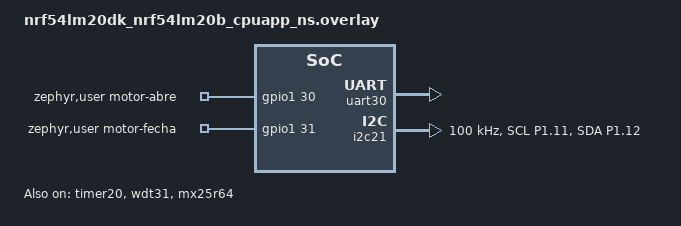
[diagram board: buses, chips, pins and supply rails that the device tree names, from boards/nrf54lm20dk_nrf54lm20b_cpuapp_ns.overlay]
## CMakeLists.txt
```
#
# Coester - SIM Connect (Gateway)
# Peripheral (interface web/celular) + Central (ate MAX_ACTUATORS
# atuadores reais via servico proprietario Coester).
#
cmake_minimum_required(VERSION 3.20.0)

find_package(Zephyr REQUIRED HINTS $ENV{ZEPHYR_BASE})
project(sim_connect_nrf54)

# NORDIC SDK APP START
target_sources(app PRIVATE
  src/main.c
  src/my_lbs.c
  src/actuator_client.c
  src/actuator_service.c
  src/uart_link.c
  src/device_health.c
  src/sensor_workq.c
  src/ads1000.c
  src/position_sensor.c
  src/torque_sensor.c
  src/torque_onoff_sensor.c
  src/sample_filter.c
  src/actuator_sensors.c
  src/actuator_params.c
  src/actuator_fsa_cfg.c
  src/actuator_torque.c
  src/watchdog.c
  src/actuator_motor.c
  src/actuator_alarm.c
  src/actuator_control.c
  src/actuator_panel.c
  src/actuator_mode.c
  src/actuator_regevent.c
)
# NORDIC SDK APP END

zephyr_library_include_directories(.)
```

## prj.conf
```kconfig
#
# Coester - SIM Connect (Gateway)
#

# Logger module
CONFIG_LOG=y

# Button and LED library
CONFIG_DK_LIBRARY=y

# --- Bluetooth LE: papel multi-role (Peripheral + varios Central) ---
CONFIG_BT=y
CONFIG_BT_PERIPHERAL=y
CONFIG_BT_CENTRAL=y
CONFIG_BT_DEVICE_NAME="Coester_Gateway"

# Nome anunciado configuravel pela propria interface web. Tentativa
# inicial (v1) usava so a Device Name padrao do GAP (servico 0x1800,
# characteristic 0x2A00) pra leitura+escrita, sem opcode customizado -
# revertido por dois motivos confirmados em campo:
#   1. Escrita nela e bloqueada por alguns navegadores/SO (Web
#      Bluetooth no Windows recusa - confirmado; escrita direta via
#      nRF Connect funciona, entao nao e o firmware).
#   2. bt_set_name() sozinho NAO persiste de forma confiavel neste
#      projeto: bt_settings_store_name() (chave embutida "bt/name" do
#      proprio Zephyr) reporta sucesso, mas o valor nao sobrevive a
#      reboot - enquanto a allow-list, no mesmo backend ZMS so que sob
#      chave nossa ("coe/al"), sobrevive normal. Bug/aspereza especifica
#      dessa integracao "bt/name" + ZMS, nao investigado a fundo.
#
# Solucao: characteristic GAP continua so LEITURA (funciona bem, e o
# navegador ja usa pra mostrar o nome atual). A ESCRITA agora e um
# opcode na nossa propria Gateway Control (GATEWAY_CTRL_SET_NAME,
# main.c) que persiste explicitamente, do nosso jeito, com o mesmo
# padrao ja confiavel da allow-list.
CONFIG_BT_DEVICE_NAME_DYNAMIC=y
CONFIG_BT_DEVICE_NAME_GATT_WRITABLE=n
CONFIG_BT_DEVICE_NAME_MAX=32

# TETO DO CONTROLADOR: o SoftDevice Controller da Nordic suporta no
# maximo 20 conexoes simultaneas somando TODOS os papeis:
#   1 interface (Peripheral) + 19 atuadores (Central) = 20
CONFIG_BT_MAX_CONN=20
CONFIG_BT_MAX_PAIRED=20

# CONFIG_BT_MAX_CONN acima e so a SOMA de todos os papeis - quantos
# podem ser Peripheral AO MESMO TEMPO e um orcamento SEPARADO
# (default 1 se nao setado). So existe 1 interface por vez, entao 1 e
# suficiente - explicito aqui, e nao no default implicito, para nao ser
# reduzido/alterado sem querer numa limpeza futura de Kconfig. Se isto
# ficar sem recurso (0 livre) enquanto a interface JA esta conectada, a
# advertising falha com HCI status 0x0d ("Limited Resources") - foi
# exatamente o que causava o loop de retentativa visto em campo quando
# um atuador reciclava a conexao com a interface ja conectada; a guarda
# em adv_work_handler() (main.c) agora evita a tentativa nesse caso, mas
# o numero fica explicito aqui pela mesma razao.
CONFIG_BT_CTLR_SDC_PERIPHERAL_COUNT=1

# Necessario para atuar como GATT Client
CONFIG_BT_GATT_CLIENT=y

# Modulo de descoberta de servicos GATT (actuator_client.c)
CONFIG_BT_GATT_DM=y

# Modulo de scan da NCS. Com os Kits B e C aposentados sobrou um unico
# filtro: o UUID do servico proprietario do atuador.
# CONFIG_BT_SCAN_UUID_CNT tem default 0 - sem reservar,
# bt_scan_filter_add() retorna -ENOMEM.
CONFIG_BT_SCAN=y
CONFIG_BT_SCAN_FILTER_ENABLE=y
CONFIG_BT_SCAN_UUID_CNT=1

# =====================================================================
# MTU - a parte mais importante desta revisao
# =====================================================================
#
# Sem estas opcoes o ATT MTU fica no default (23), ou seja 20 bytes
# uteis por notify. As respostas do protocolo proCo sao:
#
#   posicao/torque ....  18 bytes  (8 header + 10 payload)  -> cabia
#   firmware ..........  ~18 bytes                          -> cabia
#   dados gerais ......  42 bytes  (8 + 34)                 -> NAO cabia
#   curva .............  72 bytes  (8 + 64)                 -> NAO cabia
#   alarmes ........... 126 bytes  (8 + 118)                -> NAO cabia
#
# Isso explica por que a leitura de posicao/torque funcionava e as
# demais nao: era exatamente a unica que cabia em 20 bytes. O
# truncamento do bt_gatt_notify e silencioso, sem erro nenhum.
#
# Sao DOIS saltos, e os dois precisam de MTU grande:
#   atuador -> Gateway    (Gateway e Central: precisa INICIAR o MTU
#                          exchange, dai o AUTO_UPDATE_MTU abaixo)
#   Gateway -> navegador  (o navegador inicia; o Gateway so precisa de
#                          buffer)

CONFIG_BT_GATT_AUTO_UPDATE_MTU=y
CONFIG_BT_L2CAP_TX_MTU=247
CONFIG_BT_BUF_ACL_TX_SIZE=251
CONFIG_BT_BUF_ACL_RX_SIZE=251

# Data Length Extension - sem isso o MTU maior e negociado mas cada
# pacote continua fragmentado em 27 bytes de PDU, o que funciona porem
# multiplica a latencia de cada resposta grande.
CONFIG_BT_USER_DATA_LEN_UPDATE=y
CONFIG_BT_CTLR_DATA_LENGTH_MAX=251

# Mais buffers de TX: com ate 6 links centrais + a interface, o default
# vira gargalo quando varias respostas grandes chegam juntas.
#
# ATENCAO ao invariante do Zephyr:
#   CONFIG_BT_BUF_EVT_RX_COUNT > CONFIG_BT_BUF_ACL_TX_COUNT
# Cada pacote ACL enviado ao controlador gera eventos HCI de volta
# (Number of Completed Packets, principalmente). Se o host puder ter
# mais pacotes em voo do que buffers para receber os eventos que os
# liberam, ele trava esperando um buffer que so seria liberado por um
# evento sem onde chegar. Subir o ACL_TX_COUNT sem subir o EVT_RX_COUNT
# junto quebra o build com "Increase Event RX buffer count...".
# O aviso "Num of Controller's ACL packets != ACL bt_conn_tx contexts"
# no boot vem da diferenca entre estes contadores do host e o numero de
# pacotes ACL do controlador. E so um aviso de dimensionamento, nao um
# erro - mas subir o lado do controlador junto reduz o gargalo de TX
# quando varias respostas grandes chegam ao mesmo tempo.
CONFIG_BT_ATT_TX_COUNT=8
CONFIG_BT_BUF_ACL_TX_COUNT=8
CONFIG_BT_BUF_EVT_RX_COUNT=16
CONFIG_BT_CTLR_SDC_TX_PACKET_COUNT=8

# Stacks: scan + discovery + ate 19 conexoes centrais simultaneas
CONFIG_SYSTEM_WORKQUEUE_STACK_SIZE=6144
CONFIG_MAIN_STACK_SIZE=4096
CONFIG_BT_RX_STACK_SIZE=4096

# Heap: bt_gatt_dm e as multiplas conexoes centrais alocam buffers
CONFIG_HEAP_MEM_POOL_SIZE=8192

# =====================================================================
# PHY 2M
# =====================================================================
#
# Dobra a taxa no ar, reduzindo pela metade o tempo de radio de cada
# evento de conexao. Com 16 links disputando um unico radio, isso nao e
# otimizacao de luxo - e o que faz caber. O pedido e feito por link em
# actuator_client.c; se o atuador nao suportar, fica em 1M sem drama.
CONFIG_BT_CTLR_PHY_2M=y
CONFIG_BT_USER_PHY_UPDATE=y

# =====================================================================
# Persistencia da allow-list
# =====================================================================
#
# Para o nRF54L a Nordic orienta usar ZMS (Zephyr Memory Storage), nao
# NVS - o RRAM tem caracteristicas de escrita diferentes do flash. Se
# voce vier de um projeto com CONFIG_SETTINGS_NVS, esta e a migracao.
CONFIG_SETTINGS=y
CONFIG_SETTINGS_ZMS=y
CONFIG_ZMS=y
CONFIG_ZMS_LOOKUP_CACHE=y
CONFIG_ZMS_LOOKUP_CACHE_SIZE=128
CONFIG_ZMS_LOOKUP_CACHE_FOR_SETTINGS=y
CONFIG_FLASH=y
CONFIG_FLASH_MAP=y

# =====================================================================
# Agenda de radio com muitos links
# =====================================================================
#
# Limita quanto tempo um unico evento de conexao pode ocupar o radio.
# Com o default (7500 us), um link ocupado em coleta de curvas pode
# atrasar os outros 15. Reduzir aperta a coleta em lote, mas mantem o
# polling periodico regular - que e o comportamento que a demonstracao
# precisa.
#
# NOME DE KCONFIG VARIA ENTRE VERSOES DA NCS. Se o build reclamar de
# simbolo indefinido, comente esta linha: o padrao funciona, so fica
# menos justo com muitos atuadores simultaneos.
CONFIG_BT_CTLR_SDC_MAX_CONN_EVENT_LEN_DEFAULT=4000

# Descomente para ver o hexdump dos frames crus do atuador no RTT
# CONFIG_LOG_DEFAULT_LEVEL=4

# =====================================================================
# Link UART com o nRF9151 (uart_link.c)
# =====================================================================
#
# API assincrona de UART (uart_callback_set/uart_tx/uart_rx_enable) -
# mesma usada em exercises/uart-link. Ausente por padrao neste app
# porque ate a Fase 3 ele nao tinha nenhuma UART dedicada alem do
# console.
CONFIG_UART_ASYNC_API=y

# Recepcao confiavel da UARTE no nRF54L/H sem hardware flow control -
# ver nota grande no overlay de board (nrf54lm20dk_..._cpuapp_ns.overlay)
# sobre o achado em bancada (2026-08-13). Dedica TIMER20 pra contar
# bytes recebidos, evitando a perda/corrupcao de byte que a troca de
# buffer por timeout de inatividade pode causar sob latencia de
# interrupcao maior (radio BLE competindo por CPU).
CONFIG_UARTE_NRFX_UARTE_COUNT_BYTES_WITH_TIMER=y

# =====================================================================
# Sensor de posicao (potenciometro sobre ADS1000, I2C - position_sensor.c)
# =====================================================================
CONFIG_I2C=y

# Timeout por transacao I2C (default do Zephyr: 500ms) - apertado pra
# ficar mais perto da robustez do fwBLE original (TIMEOUT_TRANSACTION_
# DEFAULT=15ms em proCo/comScan.c): se uma transacao travar de verdade
# (barramento preso), o poller do sensor (ads1000.c/torque_onoff_
# sensor.c, todos na mesma fila - ver sensor_workq.c) fica bloqueado
# so' 100ms por tentativa em vez de 500ms, antes de i2c_bus_health.c
# tentar destravar o barramento - ver docs/SENSORES_I2C.md.
CONFIG_I2C_NRFX_TRANSFER_TIMEOUT=100

# Watchdog (src/watchdog.c) - task_wdt com o WDT31 como fallback de
# hardware. Motor acionado direto por GPIO: se o firmware travar com um
# pino ligado, o watchdog desliga o motor e reinicia a placa.
CONFIG_WATCHDOG=y
CONFIG_TASK_WDT=y
# Causa do ultimo reset no log de boot (saber se foi o watchdog).
CONFIG_HWINFO=y
# sys_reboot() no callback do canal estourado.
CONFIG_REBOOT=y

# Registro de eventos (src/actuator_regevent.c) na flash SPI externa
# (MX25R6435F do DK, particao event_log no overlay da placa). FLASH e
# FLASH_MAP ja estao ligados acima (settings/ZMS).
CONFIG_SPI=y
CONFIG_SPI_NOR=y
```

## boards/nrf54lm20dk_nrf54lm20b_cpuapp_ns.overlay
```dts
/*
 * Overlay para nRF54LM20-DK (target ns/TF-M - ver nota abaixo)
 * Habilita a uart30 como instancia dedicada ao link com o nRF9151.
 *
 * NAO redefine pinctrl: nrf54lm20dk_common.dtsi (arquivo nativo do
 * board, mantido pela Nordic) ja entrega current-speed, pinctrl-0/1 e
 * pinctrl-names prontos para uart30 - so falta o status="okay" abaixo.
 *
 * ACHADO EM BANCADA (2026-08-12): a primeira versao deste overlay
 * (copiada de exercises/uart-link) redefinia os pinos do zero e ERRAVA
 * - usava UART_RX em P0.08, mas o pinctrl nativo do board
 * (nrf54lm20dk_nrf54lm20_a_b-pinctrl.dtsi) diz:
 *
 *   group1: UART_TX = P0.06,  UART_RTS = P0.08
 *   group2: UART_RX = P0.07,  UART_CTS = P0.09
 *
 * P0.08 e' RTS neste board, nao RX - a redefinicao pisava em cima do
 * default correto do board com um pino errado (e descartava RTS/CTS
 * de quebra, ja que so declarava TX/RX). Sintoma visto na bancada:
 * "UART_RX_STOPPED, reason=4" (UART_ERROR_FRAMING) no lado do 91 e
 * ACK nunca recebido no lado do 54, de forma persistente.
 *
 * Fio fisico: TX do 54 = P0.06, RX do 54 = P0.07 (nao P0.08).
 *
 * NOME DO ARQUIVO IMPORTA: o nrf54-app builda para o target
 * nrf54lm20dk/nrf54lm20b/cpuapp/ns (TF-M), nao .../cpuapp (secure) como
 * exercises/uart-link. O Zephyr nomeia o overlay de board pelo target
 * INTEIRO - copiar o overlay do exercicio com o nome dele (sem "_ns")
 * faz o Zephyr simplesmente nao carregar este arquivo, sem erro de
 * build, e a uart30 fica desabilitada em silencio.
 *
 * RAIZ DA INSTABILIDADE (2026-08-13, confirmado via base de conhecimento
 * da Nordic): a UARTE do nRF54L/H (EasyDMA) so troca de buffer de
 * recepcao quando o timeout de inatividade expira, e reiniciar o
 * receptor nesse instante pode perder/corromper o byte que estava na
 * linha bem nessa hora - fica pior com latencia de interrupcao maior
 * (exatamente o efeito do radio BLE competindo por CPU/interrupcao com
 * scan+multiplas conexoes ativas). Sintoma batia exatamente com o
 * relato de outro usuario na devzone da Nordic (mesmo reason=4,
 * mesma correlacao com gaps de inatividade entre mensagens, linha
 * fisicamente limpa no osciloscopio deles). Fix documentado: dedicar
 * um TIMER pra contar bytes recebidos (CONFIG_UARTE_NRFX_UARTE_COUNT_
 * BYTES_WITH_TIMER=y no prj.conf + propriedade "timer" aqui). timer20
 * escolhido por estar livre (nada mais no projeto usa TIMER20-24).
 */

&timer20 {
	status = "okay";
};

&uart30 {
	status = "okay";
	timer = <&timer20>;
};

/*
 * I2C para o sensor de posicao (potenciometro sobre ADS1000, endereco
 * 0x49 - ver src/position_sensor.c para o porque desse endereco vs o
 * 0x92 do devices.h do proCo original).
 *
 * Sem no filho no devicetree de proposito: a leitura e crua
 * (i2c_write_read direto no registrador de conversao), no mesmo
 * espirito do exercicio validado em bancada (ncs-fund l6_e1) - evita
 * depender de um binding/driver Zephyr formal que nunca foi validado
 * (ver l7_e1, com o mesmo bug de nome de overlay descrito acima para a
 * uart30).
 *
 * i2c21 nao vem com pinctrl pronto no dtsi nativo do board (diferente
 * da uart30) - por isso, ao contrario do bloco acima, aqui precisamos
 * declarar o grupo de pinos do zero.
 */
&i2c21 {
	status = "okay";
	pinctrl-0 = <&i2c21_default>;
	pinctrl-1 = <&i2c21_sleep>;
	pinctrl-names = "default", "sleep";
	clock-frequency = <I2C_BITRATE_STANDARD>;
};

&pinctrl {
	/omit-if-no-ref/ i2c21_default: i2c21_default {
		group1 {
			psels = <NRF_PSEL(TWIM_SCL, 1, 11)>,
				    <NRF_PSEL(TWIM_SDA, 1, 12)>;
			bias-pull-up;
		};
	};
	/omit-if-no-ref/ i2c21_sleep: i2c21_sleep {
		group1 {
			psels = <NRF_PSEL(TWIM_SCL, 1, 11)>,
				    <NRF_PSEL(TWIM_SDA, 1, 12)>;
			bias-pull-up;
		};
	};
};

/*
 * Saida digital de acionamento do motor (papel atuador) - ver
 * src/actuator_motor.c. Diferente do fwBLE original (BLE/Atuador/foSeAc.c,
 * que monta uma mensagem proxiada por I2C pra uma placa FSA separada -
 * proCo/devices/devs/dev_fsa.c): o SIM Connect e' hardware unificado numa
 * placa so', sem FSA, entao o motor e' acionado direto por 2 pinos GPIO
 * do proprio nRF54 (decisao com o Felipe, 2026-09-04 - ver memoria de
 * projeto "sim-connect-command-control-port-strategy").
 *
 * P1.30 = abre, P1.31 = fecha - escolhidos em bancada, PROVISORIOS ate o
 * esquematico definitivo do circuito de acionamento existir. Trocar so'
 * os numeros de pino abaixo quando isso acontecer.
 *
 * GPIO_ACTIVE_HIGH e' um chute inicial (sem circuito de acionamento real
 * ainda pra confirmar a polaridade) - trocar pra GPIO_ACTIVE_LOW aqui se
 * o driver de motor real (rele/ponte H) for acionado em nivel baixo.
 *
 * Nao ha binding dedicado pra isto - reusa o node especial "zephyr,user"
 * (padrao do Zephyr pra GPIOs de projeto sem um binding proprio), lido em
 * actuator_motor.c via GPIO_DT_SPEC_GET(DT_PATH(zephyr_user), ..._gpios).
 */
/ {
	zephyr,user {
		motor-abre-gpios = <&gpio1 30 GPIO_ACTIVE_HIGH>;
		motor-fecha-gpios = <&gpio1 31 GPIO_ACTIVE_HIGH>;
	};
};

/* Watchdog (ver src/watchdog.c). WDT31 e' o unico WDT acessivel do lado
 * non-secure no nRF54LM20 com TF-M (WDT30 e' so' secure) - ja' e' o alias
 * watchdog0 do DK, so' vem desabilitado no dtsi.
 */
&wdt31 {
	status = "okay";
};

/* Flash SPI externa - MX25R6435F (8 MB) do DK, no spi00 (pinos nativos do
 * board: SCK P2.1, MOSI P2.2, MISO P2.4, CS P2.5, reset P2.0). Decisao
 * (2026-10-06): a placa do SIM Connect usa este mesmo chip (ou outra NOR
 * SPI compativel - o driver jedec,spi-nor le os parametros do proprio
 * chip, entao trocar e' so' devicetree). Vem desabilitada no dtsi do board.
 *
 * Uma area fixa por uso, pra um nao invadir o outro:
 *   0x000000-0x17FFFF (1,5 MB) reservado pro FOTA (slot secundario do
 *                     MCUboot, do tamanho do slot de imagem - o valor
 *                     final sai quando o MCUboot entrar; NAO usar)
 *   0x180000-0x27FFFF (1 MB)   registro de eventos (src/actuator_regevent.c,
 *                     65536 eventos de 16 bytes)
 *   0x280000-0x7FFFFF (5,5 MB) livre (curvas de torque, futuro)
 * Parametros continuam na RRAM interna (ZMS) - ver docs/REGISTRO_EVENTOS.md.
 */
&mx25r64 {
	status = "okay";

	partitions {
		compatible = "fixed-partitions";
		#address-cells = <1>;
		#size-cells = <1>;

		fota_reserved_partition: partition@0 {
			label = "fota-reserved";
			reg = <0x00000000 0x00180000>;
		};

		event_log_partition: partition@180000 {
			label = "event-log";
			reg = <0x00180000 0x00100000>;
		};
	};
};
```

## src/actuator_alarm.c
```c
/*
 * Motor de alarmes - ver actuator_alarm.h pro escopo desta primeira
 * versao (8 de ~60 alarmes do fwBLE original). O ALGORITMO abaixo
 * (tabela acao/retencao + set/release/check/get_block_mov/clears_all) e'
 * portado fielmente de BLE/Atuador/at_alarm.c - o que muda e' so' o
 * numero de linhas da tabela e as 3 dependencias externas abaixo, cada
 * uma com uma decisao de escopo explicita:
 *
 * 1. at_ctl_stop()/at_ctl_get_mov_stt() (atControle.c original) - o
 *    original tem uma dependencia CRUZADA real entre alarme e controle
 *    (atControle.c chama at_alarm_get_block_mov(), e at_alarm.c chama de
 *    volta at_ctl_stop() de dentro de al_reg_block_mov()). Como
 *    actuator_control.c ainda nao existe (passo 3), um #include direto
 *    criaria uma dependencia de link que nao compila ainda. Resolvido
 *    com o mesmo padrao de callback que actuator_client.c/my_lbs.c ja
 *    usam neste projeto pra desacoplar camadas (struct actuator_alarm_cb,
 *    ver .h) - actuator_control.c registra `stop_cb` quando existir.
 *    A segunda metade dessa dependencia (at_ctl_get_mov_stt(), usada no
 *    original só pelos modos de retenção AR_ACT_INC_INFO/AR_ACT_DEC_INFO)
 *    nao foi portada ainda porque nenhum dos 8 alarmes de hoje usa esses
 *    modos - ver o enum reduzido `actuator_alarm_retain` abaixo.
 * 2. atESDExec()/paramDado.ESDD* (al_esd_jump() original, supressao de
 *    alarme durante ESD) - ESD e' passo 6, ParamZarI e' passo 8, nenhum
 *    dos dois existe ainda. `esd_jump()` abaixo e' um stub que sempre
 *    retorna false (nenhuma supressao) - correto por enquanto porque
 *    ESD nunca esta ativo, e nenhum dos 8 alarmes de hoje e' candidato a
 *    essa supressao no original de qualquer forma (so
 *    SOBREAQUECIM/FALTA_FASE/TORQUE_AB/TORQUE_FC sao).
 * 3. atRegEvent() - portado em actuator_regevent.c. O evento leva o
 *    numero do alarme no alarm_t do fwBLE (coluna fwble_id da tabela
 *    abaixo), nao a posicao no nosso enum: EV_AL_ON/EV_AL_OFF + alarm_t
 *    e' o que um cliente do fwBLE espera. Os LOG_INF/LOG_WRN continuam
 *    pra visibilidade em RTT.
 *
 * NAO portado (avaliado e descartado, nao "esquecido"):
 * - As funcoes de display ciclico (at_alarm_get_next_view/reset_view/
 *   has_view/get_name, at_alarm_text_index[], ifIhmGetText) - existem no
 *   original pra alimentar um painel local com display. SIM Connect nao
 *   tem display fisico (ver docs/DECISOES_PRODUTO.md). Se um dia for
 *   preciso listar alarmes ativos, o caminho e' uma area/characteristic
 *   BLE nova, no mesmo espirito de PROTOCOLO_INTERFACE.md - nao esta
 *   API de ciclagem pra display.
 * - at_alarm_get_critic_fail()/at_alarm_get_pos_fail() - agregam MUITOS
 *   alarmes especificos (posicao absoluta, IO Analogica/Digital, FSA...)
 *   que nao existem no enum reduzido de hoje. Refazer quando o conjunto
 *   de 60 alarmes estiver completo.
 * - reset_check()/resetaTudo (o gatilho `dadoFSA.senFase` dentro de
 *   at_alarm_clears_all() original) - especifico de sensoriamento
 *   trifasico via FSA, que este hardware nao tem (ver
 *   docs/PORTABILIDADE_BLE_LEGADO.md e a decisao de motor por GPIO
 *   direto, memoria sim-connect-command-control-port-strategy).
 */

#include "actuator_alarm.h"
#include "actuator_regevent.h"

#include <zephyr/sys/util.h>
#include <zephyr/toolchain.h>
#include <zephyr/logging/log.h>

LOG_MODULE_REGISTER(actuator_alarm, LOG_LEVEL_INF);

/* Equivalente a al_action_t - os valores que os alarmes portados usam.
 * STOP_INCR/STOP_DECR (AA_STO_INC/AA_STO_DEC) bloqueiam so' um sentido -
 * entraram com os alarmes de torque.
 */
enum alarm_action {
	ALARM_ACTION_NONE = 0,
	ALARM_ACTION_STOP_BOTH,
	ALARM_ACTION_STOP_INCR,
	ALARM_ACTION_STOP_DECR,
};

/* Equivalente a al_retain_t - os modos que os alarmes portados usam.
 * Ainda fora (nenhum alarme portado precisa): AR_ACT_INFO, AR_CONF.
 */
enum alarm_retain {
	ALARM_RETAIN_INFO,        /* libera junto com a acao (AR_INFO) */
	ALARM_RETAIN_INFO_REMOTE, /* como INFO, mas nunca aparece num display local (AR_INFO_REMOTE) */
	ALARM_RETAIN_NOT_RETAIN,  /* libera info assim que a acao cessa, sem quitacao (AR_NOT_RETAIN) */
	ALARM_RETAIN_ACT_INC_INFO, /* release so' libera a acao com o motor FECHANDO (AR_ACT_INC_INFO) */
	ALARM_RETAIN_ACT_DEC_INFO, /* release so' libera a acao com o motor ABRINDO (AR_ACT_DEC_INFO) */
};

struct alarm_ctl_entry {
	enum alarm_action action;
	enum alarm_retain retain;
	uint8_t fwble_id; /* posicao no alarm_t do fwBLE (at_alarm.h) - id do registro de eventos */
	const char *name; /* so' pra log - nao existe no original (la' e' ifIhmGetText) */
};

/* Tabela de controle - equivalente a al_ctl[NUM_ALARMS] no original.
 * Linhas copiadas verbatim de BLE/Atuador/at_alarm.c (mesma acao/
 * retencao), na mesma ordem relativa. Adicionar um alarme = 1 linha
 * aqui (na mesma ordem do enum em actuator_alarm.h) + 1 linha no enum.
 */
static const struct alarm_ctl_entry alarm_ctl[ACTUATOR_ALARM_NUM] = {
	[ACTUATOR_ALARM_ESD_EXT] = { ALARM_ACTION_NONE, ALARM_RETAIN_INFO, 14, "ESD_EXT" },
	[ACTUATOR_ALARM_PARADA_LOCAL] = { ALARM_ACTION_NONE, ALARM_RETAIN_INFO, 15, "PARADA_LOCAL" },
	[ACTUATOR_ALARM_MODO_NAO_REMOTO] = { ALARM_ACTION_NONE, ALARM_RETAIN_INFO_REMOTE, 16,
					      "MODO_NAO_REMOTO" },
	[ACTUATOR_ALARM_LOCAL_INIBIDO] = { ALARM_ACTION_NONE, ALARM_RETAIN_NOT_RETAIN, 26,
					    "LOCAL_INIBIDO" },
	[ACTUATOR_ALARM_FAL_ACION_INV] = { ALARM_ACTION_STOP_BOTH, ALARM_RETAIN_INFO, 28,
					    "FAL_ACION_INV" },
	[ACTUATOR_ALARM_OPER_MANUAL] = { ALARM_ACTION_NONE, ALARM_RETAIN_INFO, 32, "OPER_MANUAL" },
	[ACTUATOR_ALARM_PST_EXE] = { ALARM_ACTION_NONE, ALARM_RETAIN_NOT_RETAIN, 47, "PST_EXE" },
	[ACTUATOR_ALARM_PST_FAL] = { ALARM_ACTION_NONE, ALARM_RETAIN_INFO, 48, "PST_FAL" },
	/* AL_COM_POS no fwBLE: { AA_STO_INC_DEC, AR_NOT_RETAIN } - bloqueia
	 * os dois sentidos e some sozinho quando o sensor volta a responder
	 * (sem exigir quitacao).
	 */
	[ACTUATOR_ALARM_COM_SENS_POS] = { ALARM_ACTION_STOP_BOTH, ALARM_RETAIN_NOT_RETAIN, 2,
					  "COM_SENS_POS" },
	/* Torque - linhas verbatim do at_alarm.c original:
	 *   AL_TORQUE_AB      { AA_STO_INC,     AR_ACT_INC_INFO }
	 *   AL_TORQUE_FC      { AA_STO_DEC,     AR_ACT_DEC_INFO }
	 *   AL_VALV_TRAVADA   { AA_STO_INC_DEC, AR_INFO }
	 *   AL_OPER_INCOMPLETA{ AA_NONE,        AR_INFO }
	 */
	[ACTUATOR_ALARM_TORQUE_AB] = { ALARM_ACTION_STOP_INCR, ALARM_RETAIN_ACT_INC_INFO, 11,
				       "TORQUE_AB" },
	[ACTUATOR_ALARM_TORQUE_FC] = { ALARM_ACTION_STOP_DECR, ALARM_RETAIN_ACT_DEC_INFO, 12,
				       "TORQUE_FC" },
	[ACTUATOR_ALARM_VALV_TRAVADA] = { ALARM_ACTION_STOP_BOTH, ALARM_RETAIN_INFO, 13,
					  "VALV_TRAVADA" },
	[ACTUATOR_ALARM_OPER_INCOMPLETA] = { ALARM_ACTION_NONE, ALARM_RETAIN_INFO, 17,
					     "OPER_INCOMPLETA" },
	/* AL_COM_TRQ no fwBLE: { AA_STO_INC_DEC, AR_NOT_RETAIN } - mesmo
	 * comportamento do COM_SENS_POS: bloqueia os dois sentidos e some
	 * sozinho quando o sensor volta.
	 */
	[ACTUATOR_ALARM_COM_SENS_TRQ] = { ALARM_ACTION_STOP_BOTH, ALARM_RETAIN_NOT_RETAIN, 3,
					  "COM_SENS_TRQ" },
};

/* O bitmap da area de status (actuator_alarm_info_bitmap) e' u16 */
BUILD_ASSERT(ACTUATOR_ALARM_NUM <= 16, "bitmap de alarmes da area de status tem 16 bits");

struct alarm_status {
	bool action;
	bool info;
};

static struct alarm_status alarm_stt[ACTUATOR_ALARM_NUM];
static bool block_mov;
static struct actuator_alarm_cb callbacks;

static inline bool alarm_valid(enum actuator_alarm_id alarm)
{
	return alarm < ACTUATOR_ALARM_NUM;
}

static inline const char *alarm_name(enum actuator_alarm_id alarm)
{
	return alarm_valid(alarm) ? alarm_ctl[alarm].name : "?";
}

/* Equivalente a al_esd_jump() - ver dependencia 2 no comentario do topo. */
static bool esd_jump(enum actuator_alarm_id alarm)
{
	(void)alarm;
	return false;
}

/* Equivalente a al_reg_set() - registra a transicao pra ativo. */
static void reg_set(enum actuator_alarm_id alarm)
{
	if (!alarm_stt[alarm].action) {
		alarm_stt[alarm].action = true;
		alarm_stt[alarm].info = true;
		LOG_INF("Alarme ATIVADO: %s", alarm_name(alarm));
		actuator_regevent(EV_AL_ON + alarm_ctl[alarm].fwble_id);
	}
}

/* Equivalente a al_reg_release(). */
static void reg_release(enum actuator_alarm_id alarm)
{
	if (alarm_stt[alarm].action) {
		alarm_stt[alarm].action = false;
		LOG_INF("Alarme desativado: %s", alarm_name(alarm));
		actuator_regevent(EV_AL_OFF + alarm_ctl[alarm].fwble_id);
	}
}

/* Equivalente a al_reg_block_mov() - dispara o callback de parada (se
 * registrado, ver dependencia 1 no topo) toda vez que e' chamado, igual
 * ao original (nao so' na borda).
 */
static void reg_block_mov(enum actuator_alarm_id alarm)
{
	if (!block_mov) {
		block_mov = true;
		LOG_WRN("Movimento bloqueado por alarme: %s", alarm_name(alarm));
		actuator_regevent(EV_AL_BQ);
	}
	if (callbacks.stop_cb) {
		callbacks.stop_cb();
	}
}

void actuator_alarm_init(const struct actuator_alarm_cb *cb)
{
	for (int i = 0; i < ACTUATOR_ALARM_NUM; i++) {
		alarm_stt[i].action = false;
		alarm_stt[i].info = false;
	}
	block_mov = false;

	if (cb) {
		callbacks = *cb;
	} else {
		callbacks.stop_cb = NULL;
		callbacks.mov_stt_cb = NULL;
	}

	LOG_INF("Motor de alarmes iniciado (%d de ~60 alarmes do fwBLE portados)", ACTUATOR_ALARM_NUM);
}

void actuator_alarm_set(enum actuator_alarm_id alarm)
{
	if (alarm_valid(alarm)) {
		reg_set(alarm);
	}
}

void actuator_alarm_release(enum actuator_alarm_id alarm)
{
	if (!alarm_valid(alarm)) {
		return;
	}

	switch (alarm_ctl[alarm].retain) {
	case ALARM_RETAIN_NOT_RETAIN:
		reg_release(alarm);
		alarm_stt[alarm].info = false;
		break;
	case ALARM_RETAIN_INFO:
	case ALARM_RETAIN_INFO_REMOTE:
		reg_release(alarm);
		break;
	case ALARM_RETAIN_ACT_INC_INFO:
		/* Sobretorque abrindo: o bloqueio de abrir so' sai quando o motor
		 * estiver fechando (ou pelo volante, action_clear).
		 */
		if (callbacks.mov_stt_cb && callbacks.mov_stt_cb() == ACTUATOR_MOV_DECR) {
			reg_release(alarm);
		}
		break;
	case ALARM_RETAIN_ACT_DEC_INFO:
		if (callbacks.mov_stt_cb && callbacks.mov_stt_cb() == ACTUATOR_MOV_INCR) {
			reg_release(alarm);
		}
		break;
	}

	/* Confere consistencia - se por algum motivo a acao ainda estiver
	 * ativa (ex.: retencao nao liberou), o info tem que refletir isso.
	 */
	if (alarm_stt[alarm].action) {
		alarm_stt[alarm].info = true;
	}
}

void actuator_alarm_action_clear(enum actuator_alarm_id alarm)
{
	if (alarm_valid(alarm)) {
		reg_release(alarm);
	}
}

void actuator_alarm_check(bool active, enum actuator_alarm_id alarm)
{
	if (active) {
		actuator_alarm_set(alarm);
	} else {
		actuator_alarm_release(alarm);
	}
}

bool actuator_alarm_get_action(enum actuator_alarm_id alarm)
{
	return alarm_valid(alarm) ? alarm_stt[alarm].action : false;
}

bool actuator_alarm_get_info(enum actuator_alarm_id alarm)
{
	if (!alarm_valid(alarm)) {
		return false;
	}
	/* A acao sempre e' informada, mesmo se info==false por algum motivo. */
	return alarm_stt[alarm].action || alarm_stt[alarm].info;
}

bool actuator_alarm_get_block_mov(enum actuator_mov_status at_status)
{
	for (int i = 0; i < ACTUATOR_ALARM_NUM; i++) {
		if (!alarm_stt[i].action) {
			continue;
		}

		/* Info sempre acompanha uma acao ativa. */
		alarm_stt[i].info = true;

		if (esd_jump((enum actuator_alarm_id)i)) {
			continue;
		}

		switch (alarm_ctl[i].action) {
		case ALARM_ACTION_STOP_BOTH:
			if (at_status == ACTUATOR_MOV_INCR || at_status == ACTUATOR_MOV_DECR) {
				reg_block_mov((enum actuator_alarm_id)i);
				return true;
			}
			break;
		case ALARM_ACTION_STOP_INCR:
			if (at_status == ACTUATOR_MOV_INCR) {
				reg_block_mov((enum actuator_alarm_id)i);
				return true;
			}
			break;
		case ALARM_ACTION_STOP_DECR:
			if (at_status == ACTUATOR_MOV_DECR) {
				reg_block_mov((enum actuator_alarm_id)i);
				return true;
			}
			break;
		case ALARM_ACTION_NONE:
			break;
		}
	}

	block_mov = false;
	return false;
}

void actuator_alarm_clears_all(enum actuator_alarm_clear_mode mode)
{
	bool cleaned = false;

	/* DIVERGENCIA do fwBLE: o original marca `cleaned` pra QUALQUER alarme
	 * inativo (logava EV_LOC_QT a cada chamada). Aqui so' conta quando de
	 * fato limpa uma sinalizacao (info true -> false) - importante porque
	 * o bit ack_alarm do Painel Remoto nao e' auto-limpo, entao esta
	 * funcao e' chamada a cada ciclo enquanto ele estiver setado.
	 */
	for (int i = 0; i < ACTUATOR_ALARM_NUM; i++) {
		if (!alarm_stt[i].action && alarm_stt[i].info) {
			alarm_stt[i].info = false;
			cleaned = true;
		}
	}

	if (cleaned) {
		LOG_INF("Alarmes quitados (%s)",
			mode == ACTUATOR_ALARM_CLEAR_LOCAL ? "local/BLE" : "remoto");
		actuator_regevent(mode == ACTUATOR_ALARM_CLEAR_LOCAL ? EV_LOC_QT : EV_REM_QT);
	}
}

bool actuator_alarm_get_blocked(void)
{
	return block_mov;
}

uint16_t actuator_alarm_info_bitmap(void)
{
	uint16_t bm = 0;

	for (int i = 0; i < ACTUATOR_ALARM_NUM; i++) {
		if (alarm_stt[i].action || alarm_stt[i].info) {
			bm |= BIT(i);
		}
	}
	return bm;
}
```

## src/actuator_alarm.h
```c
/*
 * Motor de alarmes do papel atuador - porta de BLE/Atuador/at_alarm.c
 * (fwBLE original, ~60 alarmes reais, ver ControleCoesterBLE) pra este
 * projeto. Ver a nota grande no .c pro raciocinio completo (o que foi
 * portado 1:1, o que foi deliberadamente reduzido/adiado, e por que).
 *
 * ESCOPO DESTA PRIMEIRA VERSAO (decidido com o Felipe, 2026-09-04): so'
 * os 8 alarmes que atControle.c/atModo.c/atESD.c/atPST.c realmente
 * consultam pra bloquear movimento ou sinalizar estado - nao os ~60 do
 * original. O MOTOR (o algoritmo: tabela acao/retencao, set/release/
 * check/get_block_mov/clears_all) e' portado por inteiro e fielmente -
 * a reducao e' so' no numero de LINHAS da tabela `alarm_ctl`, que foi
 * desenhada pra crescer por "append" (mesmo em espirito do resto do
 * projeto - ver docs/SENSORES_I2C.md, alarmes ficaram na fila la' desde
 * a portagem dos sensores).
 *
 * ATENCAO - risco de fidelidade em aberto: os valores numericos deste
 * enum (`enum actuator_alarm_id`) NAO preservam a posicao exata do
 * `alarm_t` original (que tem ~60 entradas; aqui so' declaramos as 8
 * portadas, na mesma ORDEM RELATIVA mas sem os "buracos" das que faltam).
 * Isso e' seguro enquanto nada expuser o numero do alarme cru por um
 * canal externo (BLE, RS485...) esperando bater com o valor do fwBLE -
 * ate' hoje nenhuma area do protocolo BLE documentada
 * (docs/PROTOCOLO_INTERFACE.md, docs/SENSORES_I2C.md) faz isso. Se um
 * dia isso for necessario (ex.: replicar uma area "lista de alarmes" do
 * ifFerConfig pra compatibilidade com Gateway real), os 60 valores
 * precisam ser alocados de verdade, na mesma posicao do original -
 * revisitar antes de expor isto por BLE.
 */
#ifndef ACTUATOR_ALARM_H_
#define ACTUATOR_ALARM_H_

#include <stdbool.h>
#include <stdint.h>

/* Os alarmes portados ate agora - mesma ordem relativa do enum
 * `alarm_t` original (BLE/Atuador/at_alarm.h), so sem os ~52 que faltam.
 * Adicionar um alarme novo = 1 linha aqui + 1 linha na tabela
 * `alarm_ctl` em actuator_alarm.c (ver comentario la).
 */
enum actuator_alarm_id {
	ACTUATOR_ALARM_ESD_EXT = 0,    /* Comando de ESD e visto como alarme (AL_ESD_EXT) */
	ACTUATOR_ALARM_PARADA_LOCAL,   /* AL_PARADA_LOCAL */
	ACTUATOR_ALARM_MODO_NAO_REMOTO, /* AL_MODO_NAO_REMOTO */
	ACTUATOR_ALARM_LOCAL_INIBIDO,  /* AL_LOCAL_INIBIDO */
	ACTUATOR_ALARM_FAL_ACION_INV,  /* AL_FAL_ACION_INV - acionamento invertido */
	ACTUATOR_ALARM_OPER_MANUAL,    /* AL_OPER_MANUAL - movimento pelo volante */
	ACTUATOR_ALARM_PST_EXE,        /* AL_PST_EXE - PST em execucao */
	ACTUATOR_ALARM_PST_FAL,        /* AL_PST_FAL - PST falhou */
	ACTUATOR_ALARM_COM_SENS_POS,   /* AL_COM_POS - falha de comunicacao com o sensor de posicao.
				        * Anexado no fim (fora da ordem relativa do fwBLE, onde
				        * AL_COM_POS vem antes) pra nao deslocar os bits ja
				        * existentes - ver a nota de risco de fidelidade acima. */
	/* Alarmes de torque (sptTratTrq() em sensPosTor.c) - anexados no fim
	 * pelo mesmo motivo do COM_SENS_POS (bits 9..12).
	 */
	ACTUATOR_ALARM_TORQUE_AB,       /* AL_TORQUE_AB - sobretorque abrindo; bloqueia so' abrir */
	ACTUATOR_ALARM_TORQUE_FC,       /* AL_TORQUE_FC - sobretorque fechando; bloqueia so' fechar */
	ACTUATOR_ALARM_VALV_TRAVADA,    /* AL_VALV_TRAVADA - torque nos dois sentidos; bloqueia os dois */
	ACTUATOR_ALARM_OPER_INCOMPLETA, /* AL_OPER_INCOMPLETA - comando remoto abortado por torque */
	ACTUATOR_ALARM_COM_SENS_TRQ,    /* AL_COM_TRQ - nenhuma fonte de torque online (bit 13) */
	ACTUATOR_ALARM_NUM,
};

/* Status de movimento - espelha at_ctl_mov_stt_t (atControle.h no
 * original: AS_L_SUPER/AS_L_INFER/AS_INCR/AS_DECR/AS_M_PARA). Vive aqui
 * (nao em actuator_control.c, que ainda nao existe - passo 3) porque
 * actuator_alarm_get_block_mov() precisa do tipo agora; quando
 * actuator_control.c for portado, ele deve REUSAR este mesmo enum (nao
 * duplicar) - ver nota grande no .c sobre a dependencia cruzada entre
 * controle e alarme que ja existe no original.
 */
enum actuator_mov_status {
	ACTUATOR_MOV_L_SUPER = 1,
	ACTUATOR_MOV_L_INFER,
	ACTUATOR_MOV_INCR,
	ACTUATOR_MOV_DECR,
	ACTUATOR_MOV_PARADO,
};

/* Equivalente a al_clear_mode_t - ver a decisao "BLE = Local" na memoria
 * de projeto sim-connect-command-control-port-strategy: quando
 * actuator_mode.c (passo 5) existir, uma quitacao vinda da interface BLE
 * usa ACTUATOR_ALARM_CLEAR_LOCAL, RS485/MB TCP/MQTT usam _REMOTE.
 */
enum actuator_alarm_clear_mode {
	ACTUATOR_ALARM_CLEAR_LOCAL,
	ACTUATOR_ALARM_CLEAR_REMOTE,
};

/* Hook pro passo 3 (actuator_control.c, ainda nao existe) preencher -
 * ver nota grande no .c sobre por que isto e' um callback opcional em
 * vez de um #include direto de actuator_control.h. Passar NULL em
 * actuator_alarm_init() pra "sem callback ainda" (comportamento de hoje).
 */
struct actuator_alarm_cb {
	/* Forca parada do movimento - equivalente a at_ctl_stop(ACP_ALARME)
	 * dentro de al_reg_block_mov() no original. Chamado quando
	 * actuator_alarm_get_block_mov() encontra um alarme bloqueando.
	 */
	void (*stop_cb)(void);

	/* Status de movimento atual - equivalente a at_ctl_get_mov_stt()
	 * chamado dentro de at_alarm_release() no original, so' pelos modos
	 * de retencao AR_ACT_INC_INFO/AR_ACT_DEC_INFO (alarmes de torque:
	 * o bloqueio de um sentido so' sai quando o motor vai no outro).
	 * NULL = esses alarmes nunca liberam por release (so' por
	 * actuator_alarm_action_clear()).
	 */
	enum actuator_mov_status (*mov_stt_cb)(void);
};

/* Zera o estado de todos os alarmes (equivalente a at_alarm_ini_pu()) e
 * registra os callbacks pro passo 3 (cb pode ser NULL - "sem callback
 * ainda", que e' o caso hoje).
 */
void actuator_alarm_init(const struct actuator_alarm_cb *cb);

/* Ativa o alarme indicado (equivalente a at_alarm_set()). */
void actuator_alarm_set(enum actuator_alarm_id alarm);

/* Libera o alarme indicado, respeitando o modo de retencao da tabela
 * (equivalente a at_alarm_release()).
 */
void actuator_alarm_release(enum actuator_alarm_id alarm);

/* Libera a ACAO do alarme incondicionalmente, ignorando o modo de
 * retencao (equivalente a at_alarm_action_clear()). Usado quando o
 * volante e' mexido: libera os bloqueios de torque mesmo sem inverter o
 * sentido. A sinalizacao (info) continua ate' ser quitada.
 */
void actuator_alarm_action_clear(enum actuator_alarm_id alarm);

/* Ativa ou libera conforme `active` (equivalente a at_alarm_check()). */
void actuator_alarm_check(bool active, enum actuator_alarm_id alarm);

/* true se o alarme esta ativo agora (equivalente a at_alarm_get_action()). */
bool actuator_alarm_get_action(enum actuator_alarm_id alarm);

/* true se deve ser exibido/sinalizado (ativo, ou ainda nao quitado -
 * equivalente a at_alarm_get_info()).
 */
bool actuator_alarm_get_info(enum actuator_alarm_id alarm);

/* Percorre os alarmes ativos e retorna true se algum bloqueia o
 * movimento pedido em `at_status` (so' ACTUATOR_MOV_INCR/_DECR importam
 * aqui) - equivalente a at_alarm_get_block_mov(). Chama o stop_cb
 * (se registrado) no primeiro alarme bloqueante encontrado, igual ao
 * original.
 */
bool actuator_alarm_get_block_mov(enum actuator_mov_status at_status);

/* Quita (limpa a sinalizacao de) todo alarme cuja acao ja tenha cessado -
 * equivalente a at_alarm_clears_all(). NAO afeta alarmes ainda ativos.
 */
void actuator_alarm_clears_all(enum actuator_alarm_clear_mode mode);

/* true se o motor esta bloqueado por algum alarme agora - equivalente a
 * at_alarm_get_blocked().
 */
bool actuator_alarm_get_blocked(void);

/* Bitmap dos alarmes a sinalizar (bit i = actuator_alarm_get_info(i)).
 * Nao existe no fwBLE (la' a area de alarmes e' o al_stt[] inteiro, 60
 * entradas x 2 bytes) - aqui e' um resumo compacto pra area sintetica
 * que actuator_service.c expoe pra interface. Ver a nota de risco de
 * fidelidade no topo deste header.
 */
uint16_t actuator_alarm_info_bitmap(void);

#endif /* ACTUATOR_ALARM_H_ */
```

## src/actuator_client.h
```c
/*
 * Coester - SIM Connect (Gateway)
 *
 * Actuator Manager: gerencia ate MAX_ACTUATORS conexoes Central
 * simultaneas com atuadores REAIS (produto Coester, nRF52832,
 * protocolo proCo/ifFerConfig sobre servico proprietario estilo NUS).
 *
 * Sem NENHUM parsing do protocolo proCo aqui.
 *
 * --- Escala e o teto de 20 conexoes ---
 *
 * O SoftDevice Controller da Nordic suporta no maximo 20 conexoes
 * simultaneas somando TODOS os papeis. A conta do Gateway:
 *
 *     20 total
 *      -1 interface (navegador/celular, papel Peripheral)
 *     ----
 *      19 atuadores reais
 *
 * Os Kits B e C do exercicio original da Nordic foram aposentados
 * justamente por consumirem duas dessas conexoes sem fazer parte do
 * produto. Passar de 20 exigiria trocar para o controlador do Zephyr
 * (CONFIG_BT_LL_SW_SPLIT, qualificado ate 64), mas ai o gargalo deixa
 * de ser software e vira agenda de radio.
 *
 * Com 19 + 1 interface o teto fica exatamente cheio. Se um atuador cair
 * e voltar a anunciar antes de o objeto de conexao antigo ser reciclado,
 * a tentativa de reconexao falha com -ENOMEM e o Gateway tenta de novo na
 * varredura seguinte - atraso de alguns segundos, sem consequencia.
 *
 * --- Intervalo de conexao: lento por padrao, rapido sob demanda ---
 *
 * IMPORTANTE: o enlace NAO morre por falta de trafego da aplicacao. O
 * controlador troca pacotes vazios a cada intervalo de conexao
 * automaticamente; o supervision timeout so expira quando eventos
 * consecutivos sao PERDIDOS (fora de alcance, interferencia). Fazer
 * polling a cada 5 s ou a cada 5 min e indiferente para a sobrevivencia
 * do link - quem o mantem vivo e o intervalo de conexao, nao o
 * setInterval da interface.
 *
 * O que o intervalo realmente controla e o trade-off:
 *
 *   intervalo curto (15 ms)  -> round trip ~30 ms, poucos links cabem
 *   intervalo longo (200 ms) -> round trip ~400 ms, muitos links cabem
 *
 * Polling periodico de 16 atuadores quer intervalo longo. Baixar uma
 * curva de 200 registros quer intervalo curto (a 400 ms por round trip
 * e 2 round trips por registro, seriam ~3 minutos por atuador).
 *
 * A saida e nao escolher: todo link fica LENTO por padrao, e a
 * interface pede modo RAPIDO no slot especifico antes de uma coleta em
 * lote, voltando ao lento no fim.
 */

#ifndef ACTUATOR_CLIENT_H_
#define ACTUATOR_CLIENT_H_

#ifdef __cplusplus
extern "C" {
#endif

#include <zephyr/types.h>
#include <zephyr/bluetooth/addr.h>
#include <zephyr/bluetooth/conn.h>
#include <zephyr/bluetooth/gatt.h>
#include <bluetooth/gatt_dm.h>

/* UUIDs do protocolo proprietario Coester - identicas as usadas em
 * coleta_ble/ble/protocol.py. Se o produto mudar, atualize aqui E la.
 */
#define BT_UUID_ACTUATOR_SERVICE_VAL \
	BT_UUID_128_ENCODE(0x06290001, 0x0538, 0x408d, 0x8359, 0xe83d95ae1d60)
#define BT_UUID_ACTUATOR_RX_VAL \
	BT_UUID_128_ENCODE(0x06290002, 0x0538, 0x408d, 0x8359, 0xe83d95ae1d60)
#define BT_UUID_ACTUATOR_TX_VAL \
	BT_UUID_128_ENCODE(0x06290003, 0x0538, 0x408d, 0x8359, 0xe83d95ae1d60)

#define BT_UUID_ACTUATOR_SERVICE BT_UUID_DECLARE_128(BT_UUID_ACTUATOR_SERVICE_VAL)
#define BT_UUID_ACTUATOR_RX      BT_UUID_DECLARE_128(BT_UUID_ACTUATOR_RX_VAL)
#define BT_UUID_ACTUATOR_TX      BT_UUID_DECLARE_128(BT_UUID_ACTUATOR_TX_VAL)

/* Ver a nota sobre o teto de 20 conexoes no cabecalho. Se subir isto,
 * suba CONFIG_BT_MAX_CONN junto - e nao passe de
 * 20 - (1 interface + kits de teste em uso).
 */
#define MAX_ACTUATORS 19

#define MAX_DISCOVERED 12

/* --- Formato de bytes exposto a interface web ---
 *
 * O "nome" aqui é o mesmo campo que o coleta_ble mostra como TAG do
 * atuador (scanner.py usa device.name — o Local Name do advertisement
 * BLE). O Gateway agora captura esse mesmo campo, para a interface web
 * poder identificar o atuador por nome, não só por endereço.
 *
 * Registro de STATUS (41 bytes), identico no read e no notify:
 *   [0] slot  [1] state  [2] addr_type  [3..8] MAC (invertido)
 *   [9..40] nome (32 bytes, UTF-8, preenchido com zeros a direita -
 *           trate como campo de tamanho fixo, corte no primeiro 0x00)
 *
 * Registro de DESCOBERTA (41 bytes):
 *   [0] addr_type  [1..6] MAC  [7] rssi (int8)  [8] flags
 *   [9..40] nome (mesmo formato acima)
 *
 * 32 bytes de nome porque um advertisement BLE legacy tem 31 bytes de
 * payload e cada campo gasta 2 no cabeçalho - ou seja, o maior Local
 * Name possivel tem 29 caracteres. 32 cobre isso com folga e mantem o
 * registro alinhado.
 */
#define ACTUATOR_NAME_MAX_LEN      32
#define ACTUATOR_STATUS_REC_LEN    (9 + ACTUATOR_NAME_MAX_LEN)
#define ACTUATOR_DISCOVERY_REC_LEN (9 + ACTUATOR_NAME_MAX_LEN)

#define ACTUATOR_DISCOVERY_FLAG_KNOWN BIT(0)

/** @brief Estado de um slot, do ponto de vista da interface. */
enum actuator_state {
	ACTUATOR_STATE_EMPTY = 0,     /* slot livre                             */
	ACTUATOR_STATE_WAITING = 1,   /* na allow-list, aguardando o scan achar */
	ACTUATOR_STATE_CONNECTED = 2, /* conectado, discovery em andamento      */
	ACTUATOR_STATE_READY = 3,     /* handles ok + TX assinado - pode operar */
	ACTUATOR_STATE_ERROR = 4,     /* conectou mas discovery falhou          */
};

/** @brief Perfil de velocidade do enlace com um atuador. */
enum actuator_speed {
	ACTUATOR_SPEED_SLOW = 0, /* padrao: 120-200 ms, muitos links cabem */
	ACTUATOR_SPEED_FAST = 1, /* coleta em lote: 15-30 ms, um por vez   */
};

typedef void (*actuator_raw_data_cb_t)(uint8_t slot, const uint8_t *data, uint16_t len);
typedef void (*actuator_status_cb_t)(const uint8_t *rec, uint16_t len);
typedef void (*actuator_discovery_cb_t)(const uint8_t *rec, uint16_t len);

struct actuator_manager_cb {
	actuator_raw_data_cb_t raw_data_cb;
	actuator_status_cb_t status_cb;
	actuator_discovery_cb_t discovery_cb;
};

/** @brief Inicializa o modulo. Chame ANTES de settings_load(). */
int actuator_manager_init(const struct actuator_manager_cb *cb);

int actuator_manager_add(const bt_addr_le_t *addr);
int actuator_manager_remove(const bt_addr_le_t *addr);
bool actuator_manager_is_wanted(const bt_addr_le_t *addr);

int actuator_manager_start(struct bt_conn *conn, const bt_addr_le_t *addr);
bool actuator_manager_owns_conn(struct bt_conn *conn);
void actuator_manager_conn_lost(struct bt_conn *conn);

int actuator_manager_send_to(uint8_t slot, const uint8_t *data, uint16_t len);
int actuator_manager_disconnect(uint8_t slot);

/** @brief Quantos slots têm uma conexão BLE ativa agora (qualquer
 *         estado - conectando, discovery em andamento, ou pronto),
 *         não só os PRONTOS.
 *
 *  Existe para diagnóstico: quando a advertising falha por falta de
 *  recurso no controlador (status HCI 0x0D / -ENOMEM), logar esse
 *  número junto ajuda a distinguir "genuinamente muitas conexões
 *  disputando recurso" de "algo mais específico" (ver a discussão em
 *  PROTOCOLO_INTERFACE.md sobre a trava transitória de ~34s observada
 *  em campo, cuja causa exata no controlador ainda não foi confirmada).
 */
uint8_t actuator_manager_count_connected(void);

/** @brief Quantos slots estao PRONTOS (READY) agora.
 *
 *  Existe para o LED CON_STATUS_LED_ACTUATOR do main.c: ele deve ficar
 *  aceso enquanto houver ao menos um atuador pronto, e apagar assim que
 *  o ultimo cair - o que exige recontar do zero a cada mudanca de
 *  estado, nao so ligar quando ALGUM fica pronto (senao o LED nunca
 *  apaga de volta).
 */
uint8_t actuator_manager_count_ready(void);

/* Modo rapido reverte sozinho apos este tempo. Sem isso, uma aba de
 * navegador fechada no meio de um download deixaria aquele link
 * consumindo radio indefinidamente, degradando todos os outros.
 */
#define ACTUATOR_FAST_MODE_TIMEOUT_S 180

/** @brief Coloca o enlace de um slot em modo rapido ou lento.
 *
 * @retval 0 Pedido agendado.
 * @retval -EINVAL Slot fora do intervalo.
 * @retval -ENOTCONN Slot nao conectado.
 */
int actuator_manager_set_speed(uint8_t slot, enum actuator_speed speed);

uint16_t actuator_manager_get_status_all(uint8_t *buf, uint16_t buf_len);
uint16_t actuator_manager_get_discovery_all(uint8_t *buf, uint16_t buf_len);

/** @brief Registra que um atuador foi visto no scan (endereço, RSSI e
 *         o Local Name do advertisement, se houver). Chamado para TODO
 *         atuador visto, esteja ele na allow-list ou não — alimenta o
 *         cache de descoberta e, se o endereço já for de um slot
 *         conhecido, também atualiza o nome cacheado nele.
 *
 * @param name Nome extraído do advertisement, ou string vazia/NULL se
 *             o anúncio não trouxer nome.
 */
void actuator_manager_seen(const bt_addr_le_t *addr, int8_t rssi, const char *name);

/** @brief Atualiza SÓ o nome de um endereço já conhecido (cache de
 *         descoberta e/ou slot), sem RSSI e sem criar entrada nova.
 *
 *  Existe por causa de uma particularidade do BLE: em muitos produtos,
 *  o Local Name vem no pacote de SCAN RESPONSE, não no advertisement
 *  principal - e o advertisement principal é o único que passa pelo
 *  filtro de UUID usado em actuator_manager_seen(). O bleak (Python)
 *  resolve isso escondido, porque o SO já mescla os dois pacotes antes
 *  da aplicação ver; aqui no Gateway isso tem que ser feito à mão, com um
 *  segundo callback de scan que vê TODO pacote recebido (ver
 *  bt_le_scan_cb_register no main.c). Por isso, deliberadamente, esta
 *  função só atualiza endereços que JÁ existem no cache ou numa slot -
 *  nunca cria uma entrada nova a partir de um pacote sem UUID, senão
 *  qualquer aparelho Bluetooth por perto viraria "descoberta".
 */
void actuator_manager_name_seen(const bt_addr_le_t *addr, const char *name);
void actuator_manager_clear_discovery(void);

#ifdef __cplusplus
}
#endif

#endif /* ACTUATOR_CLIENT_H_ */
```
